VERSION ""

NS_ :

BS_:

BU_: Gateway Infotainment

BO_ 100 Info_status_BMS: 1 Gateway
 SG_ INFO_BMS_SOC : 0|8@1+ (1,0) [0|100] ""  Infotainment

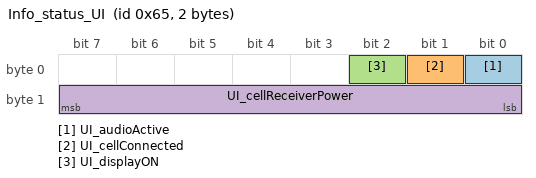
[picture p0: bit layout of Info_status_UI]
BO_ 101 Info_status_UI: 2 Infotainment
 SG_ UI_audioActive : 0|1@1+ (1,0) [0|1] ""  Gateway
 SG_ UI_cellConnected : 1|1@1+ (1,0) [0|1] ""  Gateway
 SG_ UI_displayON : 2|1@1+ (1,0) [0|1] ""  Gateway
 SG_ UI_cellReceiverPower : 8|8@1+ (1,0) [0|100] ""  Gateway
